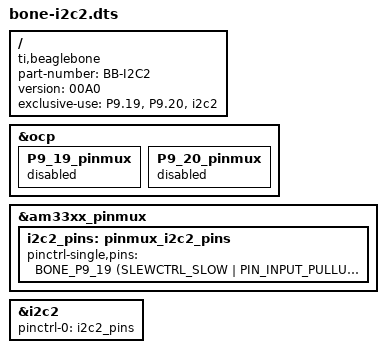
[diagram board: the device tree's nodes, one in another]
/dts-v1/;
/plugin/;

#include <dt-bindings/board/am335x-bbw-bbb-base.h>
#include <dt-bindings/pinctrl/am33xx.h>

/ {
	compatible = "ti,beaglebone", "ti,beaglebone-black", "ti,beaglebone-green", "ti,beaglebone-green-wireless";

	// identification
	part-number = "BB-I2C2";
	version = "00A0";

	// resources this cape uses
	exclusive-use =
		"P9.19",	// i2c2_scl
		"P9.20",	// i2c2_sda
		"i2c2";		// hardware ip used

	/*
	 * Free up the pins used by the cape from the pinmux helpers.
	 */
	fragment@0 {
		target = <&ocp>;
		__overlay__ {
			P9_19_pinmux { status = "disabled"; };	// i2c2_scl
			P9_20_pinmux { status = "disabled"; };	// i2c2_sda
		};
	};

	fragment@2 {
		target = <&am33xx_pinmux>;
		__overlay__ {
			i2c2_pins: pinmux_i2c2_pins {
				pinctrl-single,pins = <
					BONE_P9_19 (SLEWCTRL_SLOW | PIN_INPUT_PULLUP | MUX_MODE3)	// uart1_ctsn.i2c2_sda
					BONE_P9_20 (SLEWCTRL_SLOW | PIN_INPUT_PULLUP | MUX_MODE3)	// uart1_rtsn.i2c2_scl
				>;
			};
		};
	};

	fragment@7 {
		target = <&i2c2>;
		__overlay__ {
			pinctrl-names = "default";
			pinctrl-0 = <&i2c2_pins>;

			status = "okay";
		};
	};
};

